# GD32F527 register map
File version: 1.0
CPU: CM33 r0p1, little endian, MPU, FPU, 4 interrupt priority bits
Registers are 32-bit, read-write, reset 0x0 unless marked. A register's access mark holds for its fields unless they carry their own. Offsets are from the block's base; [hi:lo] are bit positions; 'fields as' and 'values as' point back to an identical list.

## HS_GLOBAL — USB high speed global registers
Base 0x40040000
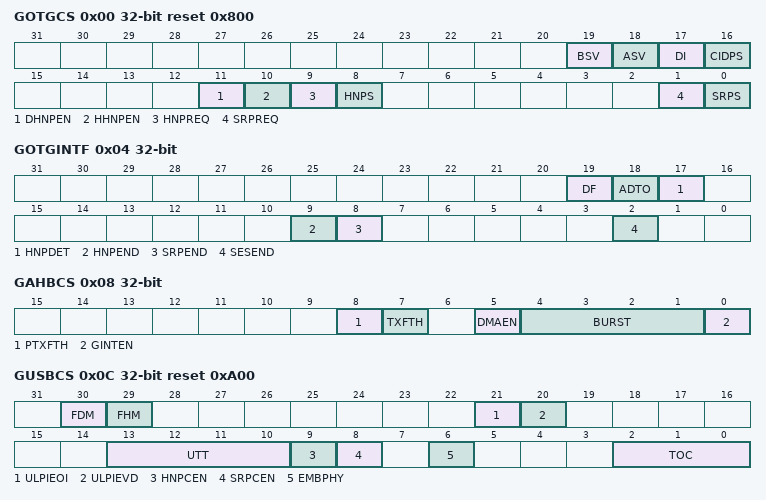
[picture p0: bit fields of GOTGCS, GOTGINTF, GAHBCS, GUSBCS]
0x00 GOTGCS access per field reset 0x800 — control and status register (GOTGCS)
  [19] BSV ro — B-session valid
  [18] ASV ro — A-session valid
  [17] DI ro — Debounce interval of a detected connection
  [16] CIDPS ro — ID pin status
  [11] DHNPEN rw — Device HNP enabled
  [10] HHNPEN rw — Host HNP enable
  [9] HNPREQ rw — HNP request
  [8] HNPS ro — Host negotiation success
  [1] SRPREQ rw — SRP request
  [0] SRPS ro — Session request success
0x04 GOTGINTF — Global OTG interrupt register (GOTGINTF)
  [19] DF — Debounce finish
  [18] ADTO — A-device timeout
  [17] HNPDET — Host negotiation detected
  [9] HNPEND
  [8] SRPEND
  [2] SESEND — Session end
0x08 GAHBCS — Global AHB configuration register (GAHBCS)
  [8] PTXFTH — Periodic TxFIFO empty level
  [7] TXFTH — TxFIFO threshold
  [5] DMAEN — DMA function enalbed
  [4:1] BURST — AHB burst type used by DMA
  [0] GINTEN — Global interrupt enable
0x0C GUSBCS reset 0xA00 — USB configuration register (GUSBCS)
  [30] FDM — Force device mode
  [29] FHM — Force host mode
  [21] ULPIEOI — ULPI external over current indicator
  [20] ULPIEVD — ULPI external VBUS driver
  [13:10] UTT — USB turnaround time
  [9] HNPCEN — HNP capability enable
  [8] SRPCEN — SRP capability enable
  [6] EMBPHY — Embedded PHY selected
  [2:0] TOC — timeout calibration
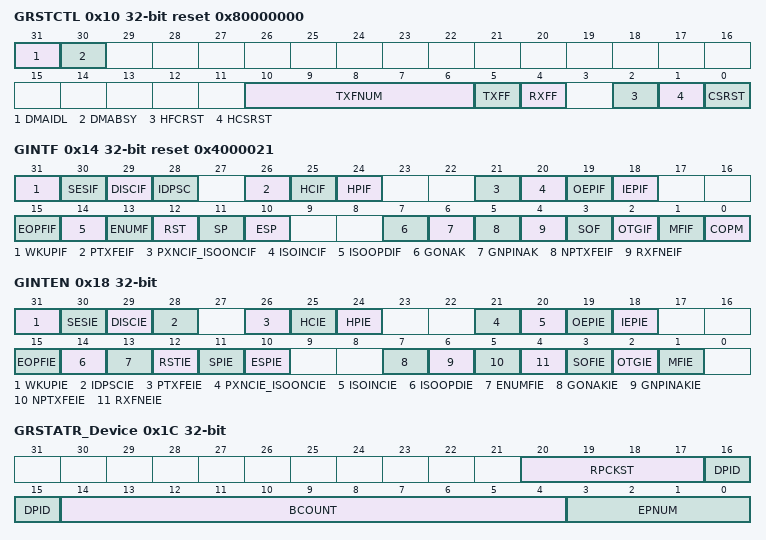
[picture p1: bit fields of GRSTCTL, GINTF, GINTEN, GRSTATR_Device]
0x10 GRSTCTL access per field reset 0x80000000 — Global reset register (GRSTCTL)
  [31] DMAIDL ro — DMA idle state
  [30] DMABSY ro — DMA Busy
  [10:6] TXFNUM rw — TxFIFO number
  [5] TXFF rw — TxFIFO flush
  [4] RXFF rw — RxFIFO flush
  [2] HFCRST rw — Host frame counter reset
  [1] HCSRST rw — HCLK soft reset
  [0] CSRST rw — Core soft reset
0x14 GINTF access per field reset 0x4000021 — Global interrupt flag register (GINTF)
  [31] WKUPIF rw — wakeup interrupt flag
  [30] SESIF rw — Session interrupt flag
  [29] DISCIF rw — Disconnect interrupt flag
  [28] IDPSC rw — ID pin status change
  [26] PTXFEIF ro — Periodic TxFIFO empty interrupt flag
  [25] HCIF ro — Host channels interrupt flag
  [24] HPIF ro — Host port interrupt flag
  [21] PXNCIF_ISOONCIF rw — periodic transfer not complete interrupt flag(Host mode)/isochronous OUT transfer not complete interrupt flag(Device mode)
  [20] ISOINCIF rw — Isochronous IN transfer Not Complete Interrupt Flag
  [19] OEPIF ro — OUT endpoint interrupt flag
  [18] IEPIF ro — IN endpoint interrupt flag
  [15] EOPFIF rw — End of periodic frame interrupt flag
  [14] ISOOPDIF rw — Isochronous OUT packet dropped interrupt flag
  [13] ENUMF rw — Enumeration finished
  [12] RST rw — USB reset
  [11] SP rw — USB suspend
  [10] ESP rw — Early suspend
  [7] GONAK ro — Global OUT NAK effective
  [6] GNPINAK ro — Global IN non-periodic NAK effective
  [5] NPTXFEIF ro — Non-periodic TxFIFO empty interrupt flag
  [4] RXFNEIF ro — RxFIFO non-empty
  [3] SOF rw — Start of frame
  [2] OTGIF ro — OTG interrupt
  [1] MFIF rw — Mode fault interrupt flag
  [0] COPM ro — Current mode of operation
0x18 GINTEN access per field — Global interrupt enable register (GINTEN)
  [31] WKUPIE rw — Wakeup interrupt enable
  [30] SESIE rw — Session interrupt enable
  [29] DISCIE rw — Disconnect interrupt enable
  [28] IDPSCIE rw — ID pin status change interrupt enable
  [26] PTXFEIE rw — Periodic TxFIFO empty interrupt enable
  [25] HCIE rw — Host channels interrupt enable
  [24] HPIE ro — Host port interrupt enable
  [21] PXNCIE_ISOONCIE rw — periodic transfer not compelete Interrupt enable(Host mode)/isochronous OUT transfer not complete interrupt enable(Device mode)
  [20] ISOINCIE rw — isochronous IN transfer not complete interrupt enable
  [19] OEPIE rw — OUT endpoints interrupt enable
  [18] IEPIE rw — IN endpoints interrupt enable
  [15] EOPFIE rw — End of periodic frame interrupt enable
  [14] ISOOPDIE rw — Isochronous OUT packet dropped interrupt enable
  [13] ENUMFIE rw — Enumeration finish enable
  [12] RSTIE rw — USB reset interrupt enable
  [11] SPIE rw — USB suspend interrupt enable
  [10] ESPIE rw — Early suspend interrupt enable
  [7] GONAKIE rw — Global OUT NAK effective interrupt enable
  [6] GNPINAKIE rw — Global non-periodic IN NAK interrupt enable
  [5] NPTXFEIE rw — Non-periodic TxFIFO empty interrupt enable
  [4] RXFNEIE rw — Receive FIFO non-empty interrupt enable
  [3] SOFIE rw — Start of frame interrupt enable
  [2] OTGIE rw — OTG interrupt enable
  [1] MFIE rw — Mode fault interrupt enable
0x1C GRSTATR_Device ro — Global Receive status read(Device mode)
  [20:17] RPCKST — Recieve packet status
  [16:15] DPID — Data PID
  [14:4] BCOUNT — Byte count
  [3:0] EPNUM — Endpoint number
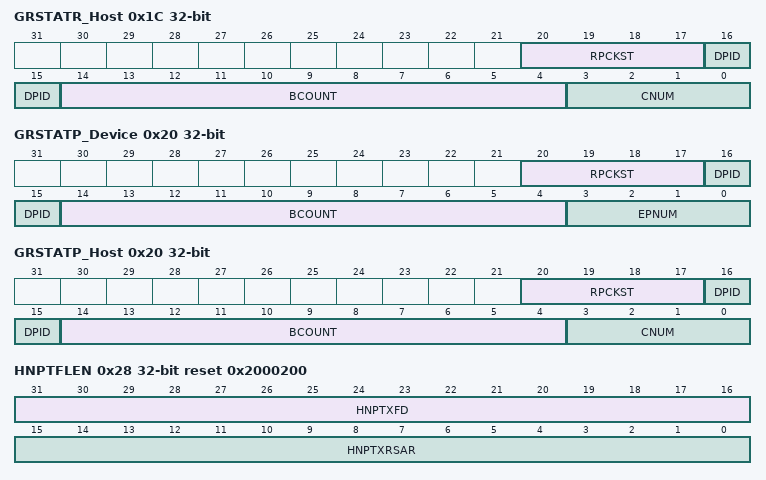
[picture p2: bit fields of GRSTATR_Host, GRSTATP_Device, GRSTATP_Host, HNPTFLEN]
0x1C GRSTATR_Host ro (alternate view of GRSTATR_Device) — Global Receive status debug read(Host mode)
  [20:17] RPCKST — Reivece packet status
  [16:15] DPID — Data PID
  [14:4] BCOUNT — Byte count
  [3:0] CNUM — Channel number
0x20 GRSTATP_Device ro — Global Receive status pop(Device mode)
  fields as GRSTATR_Device
0x20 GRSTATP_Host ro (alternate view of GRSTATP_Device) — Global Receive status debug pop(Host mode)
  fields as GRSTATR_Host
0x24 GRFLEN reset 0x200 — Global Receive FIFO size register (OTG_FS_GRFLEN)
  [15:0] RXFD — Rx FIFO depth
0x28 HNPTFLEN reset 0x2000200 — Host non-periodic transmit FIFO size register (Host mode)
  [31:16] HNPTXFD — host non-periodic TxFIFO depth
  [15:0] HNPTXRSAR — host non-periodic transmit Tx RAM start address
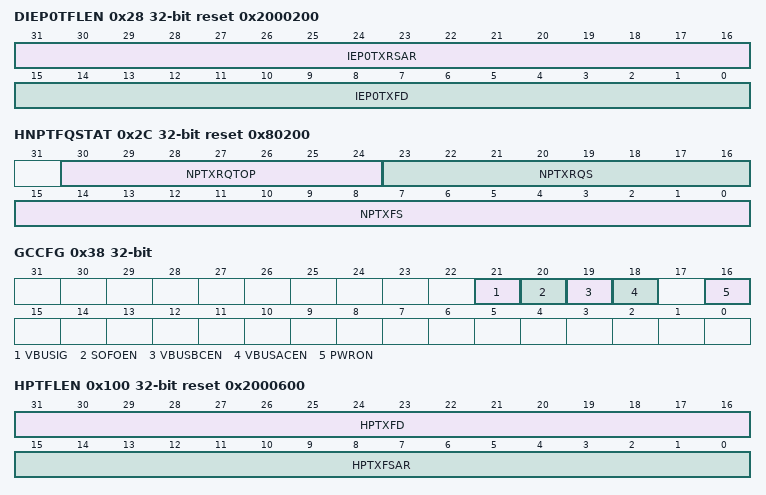
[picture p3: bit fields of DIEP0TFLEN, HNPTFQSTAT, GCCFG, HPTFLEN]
0x28 DIEP0TFLEN reset 0x2000200 (alternate view of HNPTFLEN) — Device IN endpoint 0 transmit FIFO length (Device mode)
  [31:16] IEP0TXRSAR — in endpoint 0 Tx RAM start address
  [15:0] IEP0TXFD — in endpoint 0 Tx FIFO depth
0x2C HNPTFQSTAT ro reset 0x80200 — Host non-periodic transmit FIFO/queue status register (HNPTFQSTAT)
  [30:24] NPTXRQTOP — Top entry of the non-periodic Tx request queue
  [23:16] NPTXRQS — Non-periodic transmit request queue space
  [15:0] NPTXFS — Non-periodic TxFIFO space available
0x38 GCCFG — Global core configuration register (GCCFG)
  [21] VBUSIG — VBUS ignored
  [20] SOFOEN — SOF output enable
  [19] VBUSBCEN — The VBUS B-device Comparer enable
  [18] VBUSACEN — The VBUS A-device Comparer enable
  [16] PWRON — Power on
0x3C CID reset 0x1000 — core ID register
  [31:0] CID — Core ID
0x100 HPTFLEN reset 0x2000600 — Host periodic transmit FIFO size register (HPTFLEN)
  [31:16] HPTXFD — Host periodic TxFIFO depth
  [15:0] HPTXFSAR — Host periodic TxFIFO start address
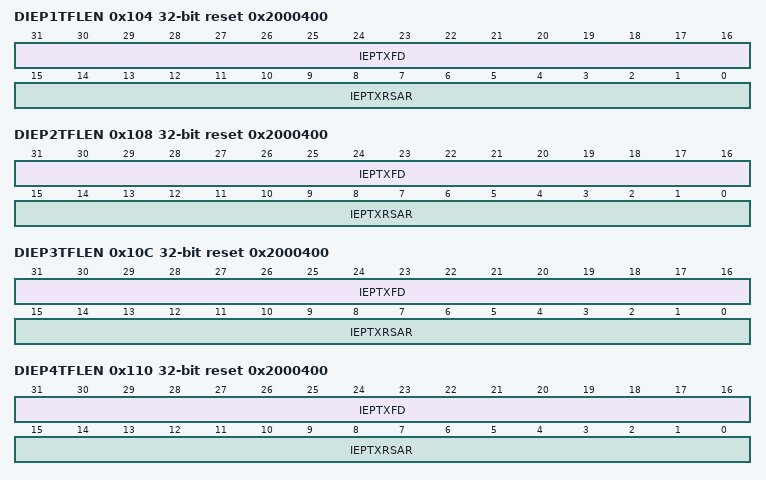
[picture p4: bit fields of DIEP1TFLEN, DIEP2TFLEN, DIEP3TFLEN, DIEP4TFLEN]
0x104 DIEP1TFLEN reset 0x2000400 — device IN endpoint transmit FIFO size register (DIEP1TFLEN)
  [31:16] IEPTXFD — IN endpoint TxFIFO depth
  [15:0] IEPTXRSAR — IN endpoint FIFO transmit RAM start address
0x108 DIEP2TFLEN reset 0x2000400 — device IN endpoint transmit FIFO size register (DIEP2TFLEN)
  fields as DIEP1TFLEN
0x10C DIEP3TFLEN reset 0x2000400 — device IN endpoint transmit FIFO size register (DIEP3TXFLEN)
  fields as DIEP1TFLEN
0x110 DIEP4TFLEN reset 0x2000400 — device IN endpoint transmit FIFO size register (DIEP4TXFLEN)
  fields as DIEP1TFLEN
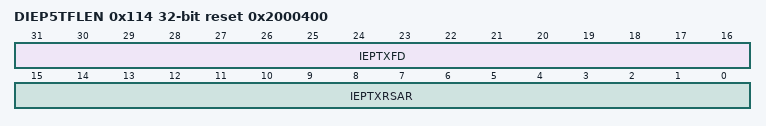
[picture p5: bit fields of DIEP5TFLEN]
0x114 DIEP5TFLEN reset 0x2000400 — device IN endpoint transmit FIFO size register (DIEP5TXFLEN)
  [31:16] IEPTXFD — IN endpoint TxFIFO depth
  [15:0] IEPTXRSAR — IN endpoint FIFO4 transmit RAM start address
